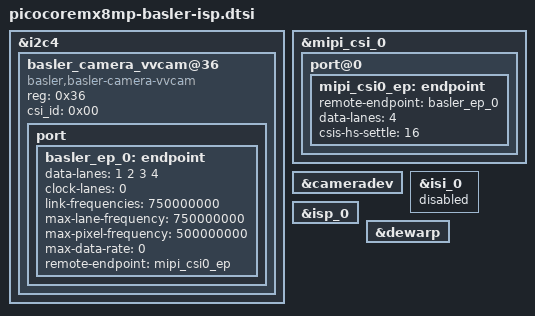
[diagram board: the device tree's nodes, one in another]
&i2c4 {
	status = "okay";
	basler_camera_vvcam@36 {
		compatible = "basler,basler-camera-vvcam", "basler-camera-vvcam";
		reg = <0x36>;
		csi_id = <0x00>;
		status = "okay";

		port {
			basler_ep_0: endpoint {
				data-lanes = <1 2 3 4>;
				clock-lanes = <0>;
				link-frequencies = /bits/ 64 <750000000>;
				max-lane-frequency = /bits/ 64 <750000000>;
				max-pixel-frequency = /bits/ 64 <500000000>;
				max-data-rate = /bits/ 64 <0>;
				remote-endpoint = <&mipi_csi0_ep>;
			};
		};
	};
};

&mipi_csi_0 {
	status = "okay";

	port@0 {
		mipi_csi0_ep: endpoint {
			remote-endpoint = <&basler_ep_0>;
			data-lanes = <4>;
			csis-hs-settle = <16>;
		};
	};
};

&cameradev {
	status = "okay";
};

&isi_0 {
	status = "disabled";
};

&isp_0 {
	status = "okay";
};

&dewarp {
	status = "okay";
};
